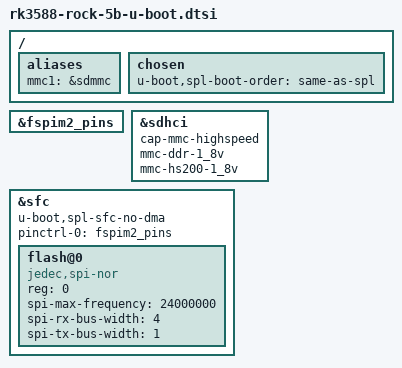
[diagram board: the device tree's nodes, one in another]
// SPDX-License-Identifier: (GPL-2.0+ OR MIT)
/*
 * Copyright (c) 2023 Collabora Ltd.
 */

#include "rk3588-u-boot.dtsi"

/ {
	aliases {
		mmc1 = &sdmmc;
	};

	chosen {
		u-boot,spl-boot-order = "same-as-spl", &sdmmc, &sdhci;
	};
};

&fspim2_pins {
	bootph-all;
};

&sdhci {
	cap-mmc-highspeed;
	mmc-ddr-1_8v;
	mmc-hs200-1_8v;
};

&sfc {
	bootph-pre-ram;
	u-boot,spl-sfc-no-dma;
	pinctrl-names = "default";
	pinctrl-0 = <&fspim2_pins>;
	#address-cells = <1>;
	#size-cells = <0>;
	status = "okay";

	flash@0 {
		bootph-pre-ram;
		compatible = "jedec,spi-nor";
		reg = <0>;
		spi-max-frequency = <24000000>;
		spi-rx-bus-width = <4>;
		spi-tx-bus-width = <1>;
	};
};
